# DP32G030 register map
File version: 1.0
CPU: CM0 r0p0, little endian, no MPU, no FPU, 4 interrupt priority bits
Registers are 32-bit, read-write, reset 0x0 unless marked. A register's access mark holds for its fields unless they carry their own. Offsets are from the block's base; [hi:lo] are bit positions.

## TIMER_BASE1 — TIMER_BASE1 unit
Base 0x40064800
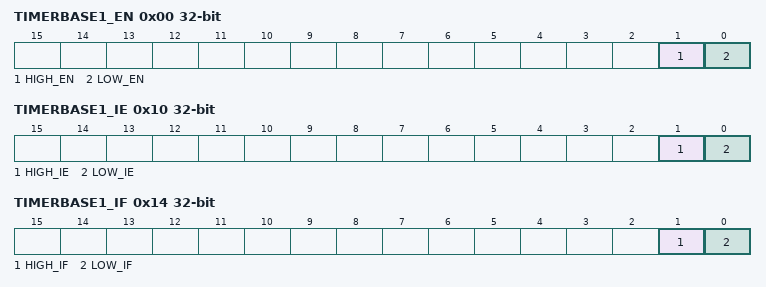
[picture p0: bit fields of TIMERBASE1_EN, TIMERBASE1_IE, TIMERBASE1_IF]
0x00 TIMERBASE1_EN — TIMER enable register
  [1] HIGH_EN — TIMERBASE HIGH Timer Enable Register
  [0] LOW_EN — TIMERBASE LOW Timer Enable Register
0x04 TIMERBASE1_DIV — TIMER Count Clock Divider Register
  [15:0] DIV — TIMERBASE Count Clock Prescaler Register 0x0000: indicates 1 division 0x0001: indicates 2 divisions ...... 0xFFFF: indicates 65536 division frequency
0x10 TIMERBASE1_IE — TIMER interrupt enable register
  [1] HIGH_IE — TIMERBASE HIGH Timer Interrupt Enable
  [0] LOW_IE — TIMERBASE LOW Timer Interrupt Enable
0x14 TIMERBASE1_IF — TIMER Interrupt Status Register
  [1] HIGH_IF — TIMERBASE HIGH Timer Interrupt Status Write 1 to clear the status.
  [0] LOW_IF — TIMERBASE LOW Timer Interrupt Status Write 1 to Clear
0x20 TIMERBASE1_HIGH_LOAD reset 0xFFFF — TIMER HIGH target configuration register
  [15:0] HIGH_LOAD — TIMERBASE HIGH Timer Target Configuration Register When the high 16bit counter counts up to the set value, the corresponding status signal is generated.
0x24 TIMERBASE1_HIGH_CNT ro — TIMER HIGH Current count value register
  [15:0] HIGH_CNT — TIMERBASE HIGH Timer Current Count Value
0x30 TIMERBASE1_LOW_LOAD reset 0xFFFF — TIMER LOW target configuration register
  [15:0] LOW_LOAD — TIMERBASE LOW Timer Target Configuration Register When the low 16bit counter counts up to the set value, the corresponding status signal is generated.
0x34 TIMERBASE1_LOW_CNT ro — TIMER LOW Current count value register
  [15:0] LOW_CNT — TIMERBASE LOW Timer Current Count Value

## TIMER_BASE2 — TIMER_BASE2 unit
Base 0x40065000
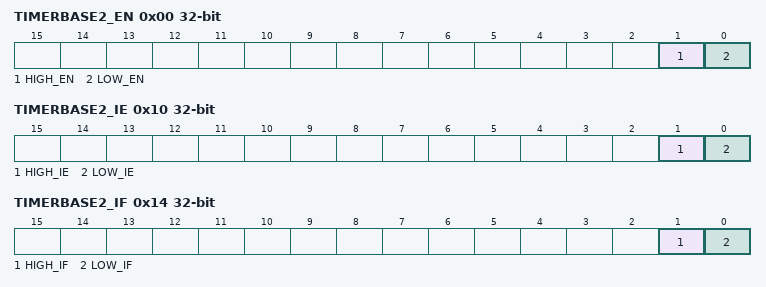
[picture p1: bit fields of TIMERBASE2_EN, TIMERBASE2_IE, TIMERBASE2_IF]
0x00 TIMERBASE2_EN — TIMER enable register
  [1] HIGH_EN — TIMERBASE HIGH Timer Enable Register
  [0] LOW_EN — TIMERBASE LOW Timer Enable Register
0x04 TIMERBASE2_DIV — TIMER Count Clock Divider Register
  [15:0] DIV — TIMERBASE Count Clock Prescaler Register 0x0000: indicates 1 division 0x0001: indicates 2 divisions ...... 0xFFFF: indicates 65536 division frequency
0x10 TIMERBASE2_IE — TIMER interrupt enable register
  [1] HIGH_IE — TIMERBASE HIGH Timer Interrupt Enable
  [0] LOW_IE — TIMERBASE LOW Timer Interrupt Enable
0x14 TIMERBASE2_IF — TIMER Interrupt Status Register
  [1] HIGH_IF — TIMERBASE HIGH Timer Interrupt Status Write 1 to clear the status.
  [0] LOW_IF — TIMERBASE LOW Timer Interrupt Status Write 1 to Clear
0x20 TIMERBASE2_HIGH_LOAD reset 0xFFFF — TIMER HIGH target configuration register
  [15:0] HIGH_LOAD — TIMERBASE HIGH Timer Target Configuration Register When the high 16bit counter counts up to the set value, the corresponding status signal is generated.
0x24 TIMERBASE2_HIGH_CNT ro — TIMER HIGH Current count value register
  [15:0] HIGH_CNT — TIMERBASE HIGH Timer Current Count Value
0x30 TIMERBASE2_LOW_LOAD reset 0xFFFF — TIMER LOW target configuration register
  [15:0] LOW_LOAD — TIMERBASE LOW Timer Target Configuration Register When the low 16bit counter counts up to the set value, the corresponding status signal is generated.
0x34 TIMERBASE2_LOW_CNT ro — TIMER LOW Current count value register
  [15:0] LOW_CNT — TIMERBASE LOW Timer Current Count Value

## IWDT — IWDT unit
Base 0x4006A000
0x00 IWDT_LOAD reset 0xFFFF — IWDT initial value register
  [19:0] IWDTLOAD — Initial value configuration register for the IWDT counter. When the IWDT starts, the counter is automatically loaded with the IWDTLOAD value and starts counting down. When the counter value reaches 0, the hardware automatically reloads the value in the IWDTLOAD register into the counter to continue the decremental count. When the first count reaches 0, an interrupt is generated. If the dog is not fed, the count is reduced to 0 again, and a reset is generated.
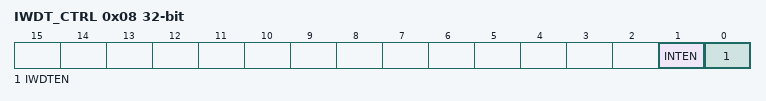
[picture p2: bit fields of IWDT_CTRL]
0x08 IWDT_CTRL — IWDT control register
  [1] INTEN — IWDT interrupt enable bit 1: Enabling 0: Prohibited
  [0] IWDTEN — IWDT start bit 1: Initiate IWDT counting 0: Stop counting
0x0C IWDT_IF — IWDT status register
  [0] IWDT_IF write-1-clears — IWDT status bit, count to 0, high valid hardware set, software write 1 clear
0x10 IWDT_FEED — IWDT feeding dog register
  [7:0] FEED — IWDT Restart Counter Registers Writing 0x55 to this register restarts the IWDT counter (feed dog operation)
